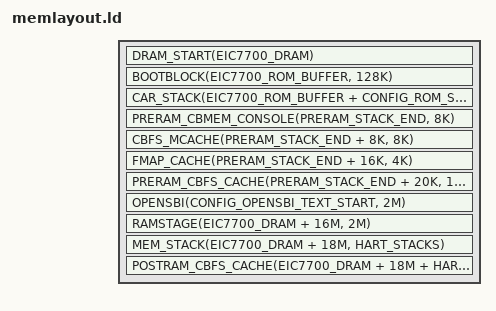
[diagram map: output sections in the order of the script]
/* SPDX-License-Identifier: GPL-2.0-only */
#include <memlayout.h>
#include <arch/header.ld>
#include <soc/addressmap.h>

#define HART_STACKS (CONFIG_MAX_CPUS * 4K)
#define PRERAM_STACK_END (EIC7700_ROM_BUFFER + CONFIG_ROM_SIZE + HART_STACKS)

SECTIONS
{
	DRAM_START(EIC7700_DRAM)
	/* SCPU supplies initialized DRAM. No cache-as-RAM setup is needed. */
	BOOTBLOCK(EIC7700_ROM_BUFFER, 128K)
	CAR_STACK(EIC7700_ROM_BUFFER + CONFIG_ROM_SIZE, HART_STACKS)
	PRERAM_CBMEM_CONSOLE(PRERAM_STACK_END, 8K)
	CBFS_MCACHE(PRERAM_STACK_END + 8K, 8K)
	FMAP_CACHE(PRERAM_STACK_END + 16K, 4K)
	PRERAM_CBFS_CACHE(PRERAM_STACK_END + 20K, 128K)

	OPENSBI(CONFIG_OPENSBI_TEXT_START, 2M)
	RAMSTAGE(EIC7700_DRAM + 16M, 2M)
	MEM_STACK(EIC7700_DRAM + 18M, HART_STACKS)
	POSTRAM_CBFS_CACHE(EIC7700_DRAM + 18M + HART_STACKS, 14M - HART_STACKS)
}
